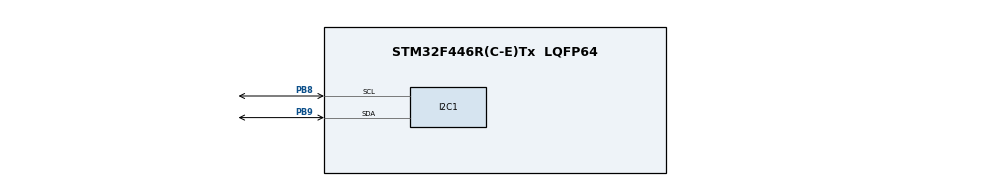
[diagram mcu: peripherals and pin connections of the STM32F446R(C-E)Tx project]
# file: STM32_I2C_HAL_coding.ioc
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Mcu.Family=STM32F4
Mcu.Name=STM32F446R(C-E)Tx
Mcu.Package=LQFP64
NVIC.PriorityGroup=NVIC_PRIORITYGROUP_4
PB8.Mode=I2C
PB8.Signal=I2C1_SCL
PB9.Mode=I2C
PB9.Signal=I2C1_SDA
ProjectManager.HeapSize=0x200
ProjectManager.StackSize=0x400
ProjectManager.TargetToolchain=STM32CubeIDE
RCC.CortexFreq_Value=16000000
RCC.USBFreq_Value=96000000
RCC.VCOOutputFreq_Value=192000000
board=custom

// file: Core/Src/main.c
/* USER CODE BEGIN Header */
/**
 ******************************************************************************
 * @file    main.c
 * @brief   OLED ssd1306 I2C HAL
 ******************************************************************************
 */
/* USER CODE END Header */
#include "main.h"
#include "i2c.h"
#include "gpio.h"

/* USER CODE BEGIN Includes */
#include "ssd1306.h"
#include "ssd1306_fonts.h"
/* USER CODE END Includes */

void SystemClock_Config(void);

int main(void)
{

	/* MCU Configuration--------------------------------------------------------*/

	/* Reset of all peripherals, Initializes the Flash interface and the Systick. */
	HAL_Init();

	/* Configure the system clock */
	SystemClock_Config();

	/* Initialize all configured peripherals */
	MX_GPIO_Init();
	MX_I2C1_Init();
	/* USER CODE BEGIN 2 */
	ssd1306_Init();

	ssd1306_Fill(Black);
	ssd1306_SetCursor(0, 0);
	ssd1306_WriteString("STM32F446", Font_11x18, White);
	ssd1306_SetCursor(0, 22);
	ssd1306_WriteString("STM32 OLED I2C", Font_7x10, White);
	ssd1306_SetCursor(0, 44);
	ssd1306_WriteString("Daniel Raj.C", Font_6x8, White);
	ssd1306_SetCursor(0, 55);
	ssd1306_WriteString("_____________", Font_6x8, White);
	ssd1306_UpdateScreen();
	/* USER CODE END 2 */

	/* Infinite loop */
	while (1)
	{

	}
}

void SystemClock_Config(void)
{
	RCC_OscInitTypeDef RCC_OscInitStruct = {0};
	RCC_ClkInitTypeDef RCC_ClkInitStruct = {0};

	/** Configure the main internal regulator output voltage
	 */
	__HAL_RCC_PWR_CLK_ENABLE();
	__HAL_PWR_VOLTAGESCALING_CONFIG(PWR_REGULATOR_VOLTAGE_SCALE3);

	/** Initializes the RCC Oscillators according to the specified parameters
	 * in the RCC_OscInitTypeDef structure.
	 */
	RCC_OscInitStruct.OscillatorType = RCC_OSCILLATORTYPE_HSI;
	RCC_OscInitStruct.HSIState = RCC_HSI_ON;
	RCC_OscInitStruct.HSICalibrationValue = RCC_HSICALIBRATION_DEFAULT;
	RCC_OscInitStruct.PLL.PLLState = RCC_PLL_NONE;
	if (HAL_RCC_OscConfig(&RCC_OscInitStruct) != HAL_OK)
	{
		Error_Handler();
	}

	/** Initializes the CPU, AHB and APB buses clocks
	 */
	RCC_ClkInitStruct.ClockType = RCC_CLOCKTYPE_HCLK|RCC_CLOCKTYPE_SYSCLK
			|RCC_CLOCKTYPE_PCLK1|RCC_CLOCKTYPE_PCLK2;
	RCC_ClkInitStruct.SYSCLKSource = RCC_SYSCLKSOURCE_HSI;
	RCC_ClkInitStruct.AHBCLKDivider = RCC_SYSCLK_DIV1;
	RCC_ClkInitStruct.APB1CLKDivider = RCC_HCLK_DIV1;
	RCC_ClkInitStruct.APB2CLKDivider = RCC_HCLK_DIV1;

	if (HAL_RCC_ClockConfig(&RCC_ClkInitStruct, FLASH_LATENCY_0) != HAL_OK)
	{
		Error_Handler();
	}
}

void Error_Handler(void)
{
	__disable_irq();
	while (1)
	{
	}
}
